# APP_ESM register map
Vendor: Texas Instruments
Peripheral module from a debugger description file (folder xwrl64xx).
Registers are 32-bit, read-write, no defined reset value unless marked. A register's access mark holds for its fields unless they carry their own. Offsets are as the file gives them; lines under a group give offsets from that group; [hi:lo] are bit positions; {n}, {i} and the like mark numbered series; 'fields as' and 'values as' point back to an identical list; <NAME> marks a mode.

## APP_ESM
0x00 ESMIEPSR1 — ESM Enable ERROR Pin Action/Response Register 1
  [31:0] IEPSET — Enable ERROR Pin Action/Response on Group 1. Read in User and Privileged mode. Write in Privileged mode only. 0 Read: Failure on channel x has no influence on ERROR pin. Write: Leaves the bit and the corresponding clear bit in the ESMIEPCR1 register unchanged. 1 Read: Failure on channel x has influence on ERROR pin. Write: Enables failure influence on ERROR pin and sets the corresponding clear bit in the ESMIEPCR1 register.
0x04 ESMIEPCR1 — ESM Disable ERROR Pin Action/Response Register 1
  [31:0] IEPCLR — Disable ERROR Pin Action/Response on Group 1. Read in User and Privileged mode. Write in Privileged mode only. 0 Read: Failure on channel x has no influence on ERROR pin. Write: Leaves the bit and the corresponding set bit in the ESMIEPSR1 register unchanged. 1 Read: Failure on channel x has influence on ERROR pin. Write: Disables failure influence on ERROR pin and clears the corresponding set bit in the ESMIEPSR1 register.
0x08 ESMIESR1 — ESM Interrupt Enable Set/Status Register 1
  [31:0] INTENSET — Set interrupt Enable Read in User and Privileged mode. Write in Privileged mode only. 0 Read: Interrupt is disabled. Write: Leaves the bit and the corresponding clear bit in the ESMIECR1 register unchanged. 1 Read: Interrupt is enabled. Write: Enables interrupt and sets the corresponding clear bit in the ESMIECR1 register.
0x0C ESMIECR1 — ESM Interrupt Enable Clear/Status Register 1
  [31:0] INTENCLR — Clear Interrupt Enable Read in User and Privileged mode. Write in Privileged mode only. 0 Read: Interrupt is disabled. Write: Leaves the bit and the corresponding set bit in the ESMIESR1 register unchanged. 1 Read: Interrupt is enabled. Write: Disables interrupt and clears the corresponding set bit in the ESMIESR1 register.
0x10 ESMILSR1 — Interrupt Level Set/Status Register 1
  [31:0] INTLVLSET — Set Interrupt Priority Read in User and Privileged mode. Write in Privileged mode only. 0 Read: Interrupt of channel x is mapped to low level interrupt line. Write: Leaves the bit and the corresponding clear bit in the ESMILCR1 register unchanged. 1 Read: Interrupt of channel x is mapped to high level interrupt line. Write: Maps interrupt of channel x to high level interrupt line and sets the corresponding clear bit in the ESMILCR1 register.
0x14 ESMILCR1 — Interrupt Level Clear/Status Register 1
  [31:0] INTLVLCLR — Clear Interrupt Priority. Read in User and Privileged mode. Write in Privileged mode only. 0 Read: Interrupt of channel x is mapped to low level interrupt line. Write: Leaves the bit and the corresponding set bit in the ESMILSR1 register unchanged. 1 Read: Interrupt of channel x is mapped to high level interrupt line. Write: Maps interrupt of channel x to low level interrupt line and clears the corresponding set bit in the ESMILSR1 register.
0x18 ESMSR1 — ESM Status Register 1
  [31:0] ESF — Error Status Flag. Provides status information on a pending error. Read in User and Privileged mode. Write in Privileged mode only. 0 Read: No error occurred; no interrupt is pending. Write: Leaves the bit unchanged. 1 Read: Error occurred; interrupt is pending. Write: Clears the bit. Note: After nRST, if one of these flags are set and the corresponding interrupt are enabled, the interrupt service routine will be called.
0x1C ESMSR2 — ESM Status Register 2
  [31:0] ESF — Error Status Flag. Provides status information on a pending error. Read in User and Privileged mode. Write in Privileged mode only. 0 Read: No error occurred; no interrupt is pending. Write: Leaves the bit unchanged. 1 Read: Error occurred; interrupt is pending. Write: Clears the bit. ESMSSR2 is not impacted by this action. Note: In normal operation the flag gets cleared when reading the appropriate vector in the ESMIOFFHR offset register. Reading ESMIOFFHR will not clear the ESMSR1 and the shadow register ESMSSR2.
0x20 ESMSR3 — ESM Status Register 3
  [31:0] ESF — Error Status Flag. Provides status information on a pending error. Read in User and Privileged mode. Write in Privileged mode only. 0 Read: No error occurred. Write: Leaves the bit unchanged. 1 Read: Error occurred. Write: Clears the bit.
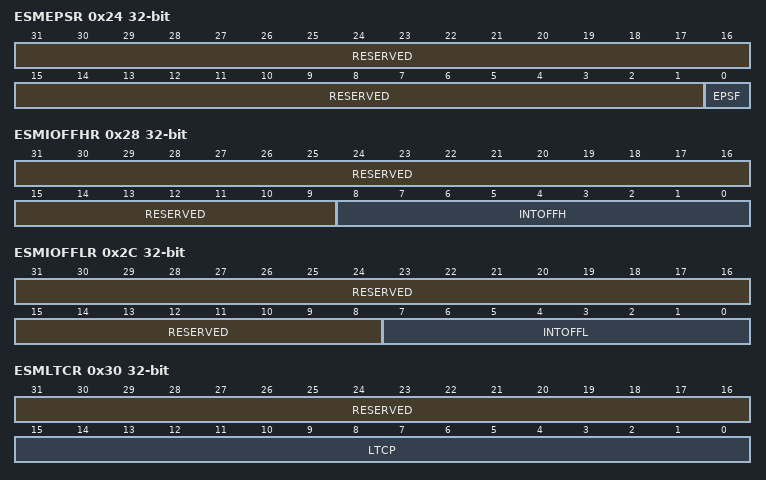
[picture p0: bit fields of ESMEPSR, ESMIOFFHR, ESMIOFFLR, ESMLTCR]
0x24 ESMEPSR — ESM ERROR Pin Status Register
  [31:1] RESERVED — Read returns 0. Writes have no effect.
  [0] EPSF — ERROR Pin Status Flag. Provides status information for the ERROR Pin. Read/Write in User and Privileged mode. 0 Read: ERROR Pin is low (active) if any error has occurred. Write: Writes have no effect. 1 Read: ERROR Pin is high if no error has occurred. Write: Writes have no effect. Note: This flag will be set to 1 after PORRST. The value will be unchanged after nRST. The ERROR pin status remains un-changed during after nRST.
0x28 ESMIOFFHR — ESM Interrupt Offset High Register
  [31:9] RESERVED — Read returns 0. Writes have no effect.
  [8:0] INTOFFH — Offset High Level Interrupt. This vector gives the channel number of the highest pending interrupt request for the high level interrupt line. Interrupts of error Group2 have higher priority than interrupts of error Group1. Inside a group, channel 0 has highest priority and channel 31 has lowest priority. User and privileged mode (read): Returns number of pending interrupt with the highest priority for the high level interrupt line. 0 No pending interrupt. 1h Interrupt pending for channel 0, error Group1. ... 20h Interrupt pending for channel 31, error Group1. 21h Interrupt pending for channel 0, error Group2. ... 40h Interrupt pending for channel 31, error Group2. 41h Interrupt pending for channel 32, error Group1. ... 60h Interrupt pending for channel 63, error Group1. Note: Reading the interrupt vector will clear the corresponding flag in the ESMSR2 register; will not clear ESMSR1 and ESMSSR2 and the offset register gets updated. User and privileged mode (write): Writes have no effect.
0x2C ESMIOFFLR — ESM Interrupt Offset Low Register
  [31:8] RESERVED — Read returns 0. Writes have no effect.
  [7:0] INTOFFL — Offset Low Level Interrupt. This vector gives the channel number of the highest pending interrupt request for the low level interrupt line. Inside a group, channel 0 has highest priority and channel 31 has lowest priority. User and privileged mode (read): Returns number of pending interrupt with the highest priority for the low level interrupt line. 0 No pending interrupt. 1h Interrupt pending for channel 0, error Group1. ... 20h Interrupt pending for channel 31, error Group1. 21h Interrupt pending for channel 32, error Group1. ... 60h Interrupt pending for channel 63, error Group1. Note: Reading the interrupt vector will not clear the corresponding flag in the ESMSR1 register. Group2 interrupts are fixed to the high level interrupt line only. User and privileged mode (write): Writes have no effect.
0x30 ESMLTCR — ESM Low-Time Counter Register
  [31:16] RESERVED — Read returns 0. Writes have no effect.
  [15:0] LTCP — ERROR Pin Low-Time Counter 16bit pre-loadable down-counter to control low-time of ERROR pin. The low-time counter is triggered by the peripheral clock (VCLK). Note: Low time counter is set to the default preload value of the ESMLTCPR in the following cases: 1. Reset (power on reset or warm reset) 2. An error occurs 3. User forces an error
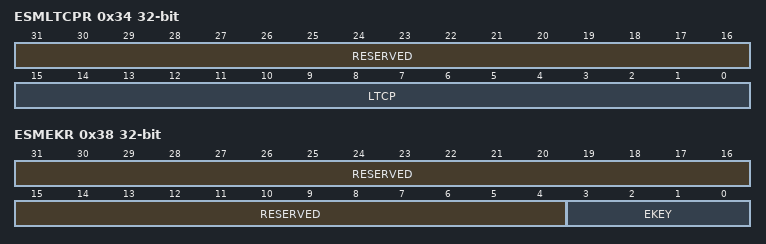
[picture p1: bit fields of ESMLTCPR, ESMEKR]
0x34 ESMLTCPR — ESM Low-Time Counter Preload Register
  [31:16] RESERVED — Read returns 0. Writes have no effect.
  [15:0] LTCP — ERROR Pin Low-Time Counter Pre-load Value 16bit pre-load value for the ERROR pin low-time counter. Note: Only LTCP.15 and LTCP.14 are configurable (privileged mode write).
0x38 ESMEKR — ESM Error Key Register
  [31:4] RESERVED — Read returns 0. Writes have no effect.
  [3:0] EKEY — Error Key. The key to reset the ERROR pin or to force an error on the ERROR pin. User and privileged mode (read): Returns current value of the EKEY. Privileged mode (write): 0 Activates normal mode (recommended default mode). Ah Forces error on ERROR pin. 5h The ERROR pin set to high when the low time counter (LTC) has completed; then the EKEY bit will switch back to normal mode (EKEY = 0000) All other values Activates normal mode.
0x3C ESMSSR2 — ESM Status Shadow Register 2
  [31:0] ESF — Error Status Flag. Shadow register for status information on pending error. Read in User and Privileged mode. Write in Privileged mode only. 0 Read: No error occurred. Write: Leaves the bit unchanged. 1 Read: Error occurred. Write: Clears the bit. ESMSR2 is not impacted by this action. Note: Errors are stored until they are cleared by the software or at power-on reset (PORRST).
0x40 ESMIEPSR4 — ESM Enable ERROR Pin Action/Response Register 4
  [31:0] IEPSET — Enable ERROR Pin Action/Response on Group 1. Read in User and Privileged mode. Write in Privileged mode only. 0 Read: Failure on channel x has no influence on ERROR pin. Write: Leaves the bit and the corresponding clear bit in the ESMIEPCR4 register unchanged. 1 Read: Failure on channel x has influence on ERROR pin. Write: Enables failure influence on ERROR pin and sets the corresponding clear bit in the ESMIEPCR4 register.
0x44 ESMIEPCR4 — ESM Disable ERROR Pin Action/Response Register 4
  [31:0] IEPCLR — Disable ERROR Pin Action/Response on Group 1. Read in User and Privileged mode. Write in Privileged mode only. 0 Read: Failure on channel x has no influence on ERROR pin. Write: Leaves the bit and the corresponding set bit in the ESMIEPSR4 register unchanged. 1 Read: Failure on channel x has influence on ERROR pin. Write: Disables failure influence on ERROR pin and clears the corresponding set bit in the ESMIEPSR4 register.
0x48 ESMIESR4 — ESM Interrupt Enable Set/Status Register 4
  [31:0] INTENSET — Set interrupt Enable Read in User and Privileged mode. Write in Privileged mode only. 0 Read: Interrupt is disabled. Write: Leaves the bit and the corresponding clear bit in the ESMIECR4 register unchanged. 1 Read: Interrupt is enabled. Write: Enables interrupt and sets the corresponding clear bit in the ESMIECR4 register.
0x4C ESMIECR4 — ESM Interrupt Enable Clear/Status Register 4
  [31:0] INTENCLR — Clear Interrupt Enable Read in User and Privileged mode. Write in Privileged mode only. 0 Read: Interrupt is disabled. Write: Leaves the bit and the corresponding set bit in the ESMIESR4 register unchanged. 1 Read: Interrupt is enabled. Write: Disables interrupt and clears the corresponding set bit in the ESMIESR4 register.
0x50 ESMILSR4 — Interrupt Level Set/Status Register 4
  [31:0] INTLVLSET — Set Interrupt Priority Read in User and Privileged mode. Write in Privileged mode only. 0 Read: Interrupt of channel x is mapped to low level interrupt line. Write: Leaves the bit and the corresponding clear bit in the ESMILCR4 register unchanged. 1 Read: Interrupt of channel x is mapped to high level interrupt line. Write: Maps interrupt of channel x to high level interrupt line and sets the corresponding clear bit in the ESMILCR4 register.
0x54 ESMILCR4 — Interrupt Level Clear/Status Register 4
  [31:0] INTLVLCLR — Clear Interrupt Priority. Read in User and Privileged mode. Write in Privileged mode only. 0 Read: Interrupt of channel x is mapped to low level interrupt line. Write: Leaves the bit and the corresponding set bit in the ESMILSR4 register unchanged. 1 Read: Interrupt of channel x is mapped to high level interrupt line. Write: Maps interrupt of channel x to low level interrupt line and clears the corresponding set bit in the ESMILSR4 register.
0x58 ESMSR4 — ESM Status Register 4
  fields as ESMSR1
0x80 ESMIEPSR7 — ESM Enable ERROR Pin Action/Response Register 7
  [31:0] IEPSET — Enable ERROR Pin Action/Response on Group 1. Read in User and Privileged mode. Write in Privileged mode only. 0 Read: Failure on channel x has no influence on ERROR pin. Write: Leaves the bit and the corresponding clear bit in the ESMIEPCR7 register unchanged. 1 Read: Failure on channel x has influence on ERROR pin. Write: Enables failure influence on ERROR pin and sets the corresponding clear bit in the ESMIEPCR7 register.
0x84 ESMIEPCR7 — ESM Disable ERROR Pin Action/Response Register 7
  [31:0] IEPCLR — Disable ERROR Pin Action/Response on Group 1. Read in User and Privileged mode. Write in Privileged mode only. 0 Read: Failure on channel x has no influence on ERROR pin. Write: Leaves the bit and the corresponding set bit in the ESMIEPSR7 register unchanged. 1 Read: Failure on channel x has influence on ERROR pin. Write: Disables failure influence on ERROR pin and clears the corresponding set bit in the ESMIEPSR7 register.
0x88 ESMIESR7 — ESM Interrupt Enable Set/Status Register 7
  [31:0] INTENSET — Set interrupt Enable Read in User and Privileged mode. Write in Privileged mode only. 0 Read: Interrupt is disabled. Write: Leaves the bit and the corresponding clear bit in the ESMIECR7 register unchanged. 1 Read: Interrupt is enabled. Write: Enables interrupt and sets the corresponding clear bit in the ESMIECR7 register.
0x8C ESMIECR7 — ESM Interrupt Enable Clear/Status Register 7
  [31:0] INTENCLR — Clear Interrupt Enable Read in User and Privileged mode. Write in Privileged mode only. 0 Read: Interrupt is disabled. Write: Leaves the bit and the corresponding set bit in the ESMIESR7 register unchanged. 1 Read: Interrupt is enabled. Write: Disables interrupt and clears the corresponding set bit in the ESMIESR7 register.
0x90 ESMILSR7 — Interrupt Level Set/Status Register 7
  [31:0] INTLVLSET — Set Interrupt Priority Read in User and Privileged mode. Write in Privileged mode only. 0 Read: Interrupt of channel x is mapped to low level interrupt line. Write: Leaves the bit and the corresponding clear bit in the ESMILCR7 register unchanged. 1 Read: Interrupt of channel x is mapped to high level interrupt line. Write: Maps interrupt of channel x to high level interrupt line and sets the corresponding clear bit in the ESMILCR7 register.
0x94 ESMILCR7 — Interrupt Level Clear/Status Register 7
  [31:0] INTLVLCLR — Clear Interrupt Priority. Read in User and Privileged mode. Write in Privileged mode only. 0 Read: Interrupt of channel x is mapped to low level interrupt line. Write: Leaves the bit and the corresponding set bit in the ESMILSR7 register unchanged. 1 Read: Interrupt of channel x is mapped to high level interrupt line. Write: Maps interrupt of channel x to low level interrupt line and clears the corresponding set bit in the ESMILSR7 register.
0x98 ESMSR7 — ESM Status Register 7
  fields as ESMSR1
0xC0 ESMIEPSR10 — ESM Enable ERROR Pin Action/Response Register 10
  [31:0] IEPSET — Enable ERROR Pin Action/Response on Group 1. Read in User and Privileged mode. Write in Privileged mode only. 0 Read: Failure on channel x has no influence on ERROR pin. Write: Leaves the bit and the corresponding clear bit in the ESMIEPCR10 register unchanged. 1 Read: Failure on channel x has influence on ERROR pin. Write: Enables failure influence on ERROR pin and sets the corresponding clear bit in the ESMIEPCR10 register.
0xC4 ESMIEPCR10 — ESM Disable ERROR Pin Action/Response Register 10
  [31:0] IEPCLR — Disable ERROR Pin Action/Response on Group 1. Read in User and Privileged mode. Write in Privileged mode only. 0 Read: Failure on channel x has no influence on ERROR pin. Write: Leaves the bit and the corresponding set bit in the ESMIEPSR10 register unchanged. 1 Read: Failure on channel x has influence on ERROR pin. Write: Disables failure influence on ERROR pin and clears the corresponding set bit in the ESMIEPSR10 register.
0xC8 ESMIESR10 — ESM Interrupt Enable Set/Status Register 10
  [31:0] INTENSET — Set interrupt Enable Read in User and Privileged mode. Write in Privileged mode only. 0 Read: Interrupt is disabled. Write: Leaves the bit and the corresponding clear bit in the ESMIECR10 register unchanged. 1 Read: Interrupt is enabled. Write: Enables interrupt and sets the corresponding clear bit in the ESMIECR10 register.
0xCC ESMIECR10 — ESM Interrupt Enable Clear/Status Register 10
  [31:0] INTENCLR — Clear Interrupt Enable Read in User and Privileged mode. Write in Privileged mode only. 0 Read: Interrupt is disabled. Write: Leaves the bit and the corresponding set bit in the ESMIESR10 register unchanged. 1 Read: Interrupt is enabled. Write: Disables interrupt and clears the corresponding set bit in the ESMIESR10 register.
0xD0 ESMILSR10 — Interrupt Level Set/Status Register 10
  [31:0] INTLVLSET — Set Interrupt Priority Read in User and Privileged mode. Write in Privileged mode only. 0 Read: Interrupt of channel x is mapped to low level interrupt line. Write: Leaves the bit and the corresponding clear bit in the ESMILCR10 register unchanged. 1 Read: Interrupt of channel x is mapped to high level interrupt line. Write: Maps interrupt of channel x to high level interrupt line and sets the corresponding clear bit in the ESMILCR10 register.
0xD4 ESMILCR10 — Interrupt Level Clear/Status Register 10
  [31:0] INTLVLCLR — Clear Interrupt Priority. Read in User and Privileged mode. Write in Privileged mode only. 0 Read: Interrupt of channel x is mapped to low level interrupt line. Write: Leaves the bit and the corresponding set bit in the ESMILSR10 register unchanged. 1 Read: Interrupt of channel x is mapped to high level interrupt line. Write: Maps interrupt of channel x to low level interrupt line and clears the corresponding set bit in the ESMILSR10 register.
0xD8 ESMSR10 — ESM Status Register 10
  fields as ESMSR1
